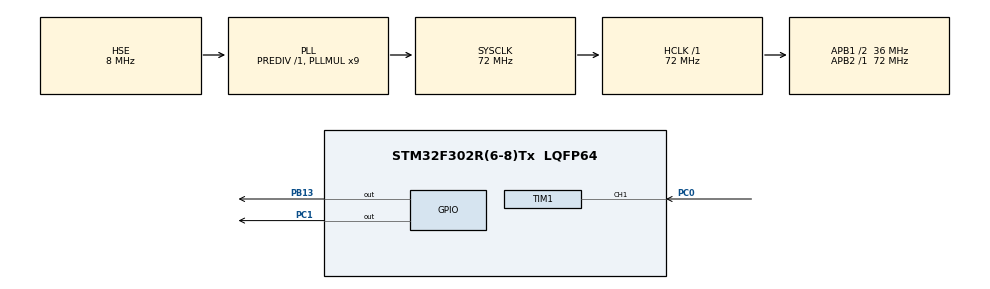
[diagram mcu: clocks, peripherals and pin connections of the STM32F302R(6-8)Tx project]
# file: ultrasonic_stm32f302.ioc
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Mcu.Family=STM32F3
Mcu.Name=STM32F302R(6-8)Tx
Mcu.Package=LQFP64
NVIC.PriorityGroup=NVIC_PRIORITYGROUP_0
NVIC.TIM1_CC_IRQn=true\:0\:0\:false\:false\:true\:true\:true\:true
PA13.Mode=Serial_Wire
PA13.Signal=SYS_JTMS-SWDIO
PA14.Mode=Serial_Wire
PA14.Signal=SYS_JTCK-SWCLK
PB13.Signal=GPIO_Output
PC0.Signal=S_TIM1_CH1
PC1.Signal=GPIO_Output
PF0-OSC_IN.Mode=HSE-External-Oscillator
PF0-OSC_IN.Signal=RCC_OSC_IN
PF1-OSC_OUT.Mode=HSE-External-Oscillator
PF1-OSC_OUT.Signal=RCC_OSC_OUT
ProjectManager.HeapSize=0x200
ProjectManager.StackSize=0x400
ProjectManager.TargetToolchain=STM32CubeIDE
RCC.AHBFreq_Value=72000000
RCC.APB1CLKDivider=RCC_HCLK_DIV2
RCC.APB1Freq_Value=36000000
RCC.APB1TimFreq_Value=72000000
RCC.APB2Freq_Value=72000000
RCC.APB2TimFreq_Value=72000000
RCC.CortexFreq_Value=72000000
RCC.HCLKFreq_Value=72000000
RCC.HSE_VALUE=8000000
RCC.HSI_VALUE=8000000
RCC.LSE_VALUE=32768
RCC.PLLM=8
RCC.PLLMUL=RCC_PLL_MUL9
RCC.PLLN=336
RCC.PLLP=RCC_PLLP_DIV4
RCC.PLLQ=7
RCC.PLLSourceVirtual=RCC_PLLSOURCE_HSE
RCC.SYSCLKFreq_VALUE=72000000
RCC.SYSCLKSourceVirtual=RCC_SYSCLKSOURCE_PLLCLK
RCC.USBFreq_Value=72000000
SH.S_TIM1_CH1.0=TIM1_CH1,Input_Capture1_from_TI1
TIM1.Channel-Input_Capture1_from_TI1=TIM_CHANNEL_1
TIM1.Period=65535-1
TIM1.Prescaler=72-1
VP_TIM1_VS_ClockSourceINT.Mode=Internal
board=NUCLEO-F302R8

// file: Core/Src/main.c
/* USER CODE BEGIN Header */
/**
  ******************************************************************************
  * @file           : main.c
  * @brief          : Main program body
  ******************************************************************************
  * @attention
  *
  * Copyright (c) 2024 STMicroelectronics.
  * All rights reserved.
  *
  * This software is licensed under terms that can be found in the LICENSE file
  * in the root directory of this software component.
  * If no LICENSE file comes with this software, it is provided AS-IS.
  *
  ******************************************************************************
  */
/* USER CODE END Header */
#include "main.h"

/* USER CODE BEGIN PM */
uint32_t pMillis=0;
uint32_t Value1=0;
uint32_t Value2=0;
uint32_t Distance=0;
uint32_t Distance_in_cm=0;
uint8_t count=0;
uint8_t counter1=0;
uint8_t counter2=0;
uint32_t tim1=0;
uint32_t tim2=0;

/* USER CODE END PM */

TIM_HandleTypeDef htim1;

void SystemClock_Config(void);
static void MX_GPIO_Init(void);
static void MX_TIM1_Init(void);
/* USER CODE BEGIN PFP */
uint32_t val1 = 0;
uint32_t val2 = 0;
uint32_t difference = 0;
uint8_t is_first_value_captured = 0;  // is the first value captured ?
uint32_t distance  = 0;
/* USER CODE END PFP */

/* USER CODE BEGIN 0 */
void delay_us(uint16_t us)
{
	__HAL_TIM_SET_COUNTER(&htim1,0);
	while(__HAL_TIM_GET_COUNTER(&htim1)<us);
}
void ultrasonic_read()
{
	HAL_GPIO_WritePin(GPIOC, GPIO_PIN_1, GPIO_PIN_SET);
	delay_us(10);
	HAL_GPIO_WritePin(GPIOC, GPIO_PIN_1, GPIO_PIN_RESET);
	__HAL_TIM_ENABLE_IT(&htim1,TIM_IT_CC1);
}
void HAL_TIM_IC_CaptureCallback(TIM_HandleTypeDef *htim)
{
//if(htim->Channel==HAL_TIM_ACTIVE_CHANNEL_1)
//{
	if(is_first_value_captured==0)
	{
		val1=HAL_TIM_ReadCapturedValue(htim, TIM_CHANNEL_1);
		is_first_value_captured=1;
	__HAL_TIM_SET_CAPTUREPOLARITY(htim,TIM_CHANNEL_1,TIM_INPUTCHANNELPOLARITY_FALLING);
	}
	else if(is_first_value_captured==1)
	{
		val2=HAL_TIM_ReadCapturedValue(htim, TIM_CHANNEL_1);
		__HAL_TIM_SET_COUNTER(htim,0);

		if(val2>val1)
		{
			difference=val2-val1;
		}
		else if(val1>val2)
		{
			difference=(0xffff-val1)+val2;
		}
		distance=difference*0.034/2;
		is_first_value_captured=0;

		__HAL_TIM_SET_CAPTUREPOLARITY(htim,TIM_CHANNEL_1,TIM_INPUTCHANNELPOLARITY_RISING);
		__HAL_TIM_DISABLE_IT(&htim1,TIM_IT_CC1);
	}
//}

}

/* USER CODE END 0 */

int main(void)
{

  /* MCU Configuration--------------------------------------------------------*/

  /* Reset of all peripherals, Initializes the Flash interface and the Systick. */
  HAL_Init();

  /* Configure the system clock */
  SystemClock_Config();

  /* Initialize all configured peripherals */
  MX_GPIO_Init();
  MX_TIM1_Init();
  /* USER CODE BEGIN 2 */
//HAL_TIM_Base_Start(&htim1);
//HAL_TIM_Base_Start_IT(&htim6);
HAL_TIM_IC_Start_IT(&htim1, TIM_CHANNEL_1);
//HAL_GPIO_WritePin(GPIOB, GPIO_PIN_13, GPIO_PIN_RESET);
  /* USER CODE END 2 */

  /* Infinite loop */
  /* USER CODE BEGIN WHILE */
  while (1)
  {
	  if(HAL_GetTick()-tim1>100)
	  {
		  tim1=HAL_GetTick();
		  ultrasonic_read();
	  }

	  if(HAL_GetTick()-tim2>500)
	  {
		  tim2=HAL_GetTick();
		  HAL_GPIO_TogglePin(GPIOB, GPIO_PIN_13);
	  }

//	  HAL_GPIO_TogglePin(GPIOB, GPIO_PIN_13);
//	  delay_us(10000);
    /* USER CODE END WHILE */

    /* USER CODE BEGIN 3 */

//                         using blocking mode             //

/*	  HAL_GPIO_WritePin(GPIOB, GPIO_PIN_13, GPIO_PIN_SET);
	  __HAL_TIM_SET_COUNTER(&htim1,0);
	  while(__HAL_TIM_GET_COUNTER(&htim1)<10);
	  HAL_GPIO_WritePin(GPIOB, GPIO_PIN_13, GPIO_PIN_RESET);
	  pMillis=HAL_GetTick();

	   while (!(HAL_GPIO_ReadPin (GPIOC, GPIO_PIN_0)) && pMillis + 10 >  HAL_GetTick());
	    Value1 = __HAL_TIM_GET_COUNTER (&htim1);

	    pMillis = HAL_GetTick(); // used this to avoid infinite while loop (for timeout)
	    // wait for the echo pin to go low
	    while ((HAL_GPIO_ReadPin (GPIOC, GPIO_PIN_0)) && pMillis + 50 > HAL_GetTick());
	    Value2 = __HAL_TIM_GET_COUNTER (&htim1);

	    Distance = (Value2-Value1)* 0.034/2;
	    HAL_Delay(50);  */

  }
  /* USER CODE END 3 */
}

void SystemClock_Config(void)
{
  RCC_OscInitTypeDef RCC_OscInitStruct = {0};
  RCC_ClkInitTypeDef RCC_ClkInitStruct = {0};
  RCC_PeriphCLKInitTypeDef PeriphClkInit = {0};

  /** Initializes the RCC Oscillators according to the specified parameters
  * in the RCC_OscInitTypeDef structure.
  */
  RCC_OscInitStruct.OscillatorType = RCC_OSCILLATORTYPE_HSE;
  RCC_OscInitStruct.HSEState = RCC_HSE_ON;
  RCC_OscInitStruct.HSEPredivValue = RCC_HSE_PREDIV_DIV1;
  RCC_OscInitStruct.HSIState = RCC_HSI_ON;
  RCC_OscInitStruct.PLL.PLLState = RCC_PLL_ON;
  RCC_OscInitStruct.PLL.PLLSource = RCC_PLLSOURCE_HSE;
  RCC_OscInitStruct.PLL.PLLMUL = RCC_PLL_MUL9;
  if (HAL_RCC_OscConfig(&RCC_OscInitStruct) != HAL_OK)
  {
    Error_Handler();
  }

  /** Initializes the CPU, AHB and APB buses clocks
  */
  RCC_ClkInitStruct.ClockType = RCC_CLOCKTYPE_HCLK|RCC_CLOCKTYPE_SYSCLK
                              |RCC_CLOCKTYPE_PCLK1|RCC_CLOCKTYPE_PCLK2;
  RCC_ClkInitStruct.SYSCLKSource = RCC_SYSCLKSOURCE_PLLCLK;
  RCC_ClkInitStruct.AHBCLKDivider = RCC_SYSCLK_DIV1;
  RCC_ClkInitStruct.APB1CLKDivider = RCC_HCLK_DIV2;
  RCC_ClkInitStruct.APB2CLKDivider = RCC_HCLK_DIV1;

  if (HAL_RCC_ClockConfig(&RCC_ClkInitStruct, FLASH_LATENCY_2) != HAL_OK)
  {
    Error_Handler();
  }
  PeriphClkInit.PeriphClockSelection = RCC_PERIPHCLK_TIM1;
  PeriphClkInit.Tim1ClockSelection = RCC_TIM1CLK_HCLK;
  if (HAL_RCCEx_PeriphCLKConfig(&PeriphClkInit) != HAL_OK)
  {
    Error_Handler();
  }
}

static void MX_TIM1_Init(void)
{

  TIM_ClockConfigTypeDef sClockSourceConfig = {0};
  TIM_MasterConfigTypeDef sMasterConfig = {0};
  TIM_IC_InitTypeDef sConfigIC = {0};

  htim1.Instance = TIM1;
  htim1.Init.Prescaler = 72-1;
  htim1.Init.CounterMode = TIM_COUNTERMODE_UP;
  htim1.Init.Period = 65535-1;
  htim1.Init.ClockDivision = TIM_CLOCKDIVISION_DIV1;
  htim1.Init.RepetitionCounter = 0;
  htim1.Init.AutoReloadPreload = TIM_AUTORELOAD_PRELOAD_DISABLE;
  if (HAL_TIM_Base_Init(&htim1) != HAL_OK)
  {
    Error_Handler();
  }
  sClockSourceConfig.ClockSource = TIM_CLOCKSOURCE_INTERNAL;
  if (HAL_TIM_ConfigClockSource(&htim1, &sClockSourceConfig) != HAL_OK)
  {
    Error_Handler();
  }
  if (HAL_TIM_IC_Init(&htim1) != HAL_OK)
  {
    Error_Handler();
  }
  sMasterConfig.MasterOutputTrigger = TIM_TRGO_RESET;
  sMasterConfig.MasterOutputTrigger2 = TIM_TRGO2_RESET;
  sMasterConfig.MasterSlaveMode = TIM_MASTERSLAVEMODE_DISABLE;
  if (HAL_TIMEx_MasterConfigSynchronization(&htim1, &sMasterConfig) != HAL_OK)
  {
    Error_Handler();
  }
  sConfigIC.ICPolarity = TIM_INPUTCHANNELPOLARITY_RISING;
  sConfigIC.ICSelection = TIM_ICSELECTION_DIRECTTI;
  sConfigIC.ICPrescaler = TIM_ICPSC_DIV1;
  sConfigIC.ICFilter = 0;
  if (HAL_TIM_IC_ConfigChannel(&htim1, &sConfigIC, TIM_CHANNEL_1) != HAL_OK)
  {
    Error_Handler();
  }

}

static void MX_GPIO_Init(void)
{
  GPIO_InitTypeDef GPIO_InitStruct = {0};

  /* GPIO Ports Clock Enable */
  __HAL_RCC_GPIOF_CLK_ENABLE();
  __HAL_RCC_GPIOC_CLK_ENABLE();
  __HAL_RCC_GPIOB_CLK_ENABLE();
  __HAL_RCC_GPIOA_CLK_ENABLE();

  /*Configure GPIO pin Output Level */
  HAL_GPIO_WritePin(GPIOC, GPIO_PIN_1, GPIO_PIN_RESET);

  /*Configure GPIO pin Output Level */
  HAL_GPIO_WritePin(GPIOB, GPIO_PIN_13, GPIO_PIN_RESET);

  /*Configure GPIO pin : PC1 */
  GPIO_InitStruct.Pin = GPIO_PIN_1;
  GPIO_InitStruct.Mode = GPIO_MODE_OUTPUT_PP;
  GPIO_InitStruct.Pull = GPIO_NOPULL;
  GPIO_InitStruct.Speed = GPIO_SPEED_FREQ_LOW;
  HAL_GPIO_Init(GPIOC, &GPIO_InitStruct);

  /*Configure GPIO pin : PB13 */
  GPIO_InitStruct.Pin = GPIO_PIN_13;
  GPIO_InitStruct.Mode = GPIO_MODE_OUTPUT_PP;
  GPIO_InitStruct.Pull = GPIO_NOPULL;
  GPIO_InitStruct.Speed = GPIO_SPEED_FREQ_LOW;
  HAL_GPIO_Init(GPIOB, &GPIO_InitStruct);

}

void Error_Handler(void)
{
  __disable_irq();
  while (1)
  {
  }
}
